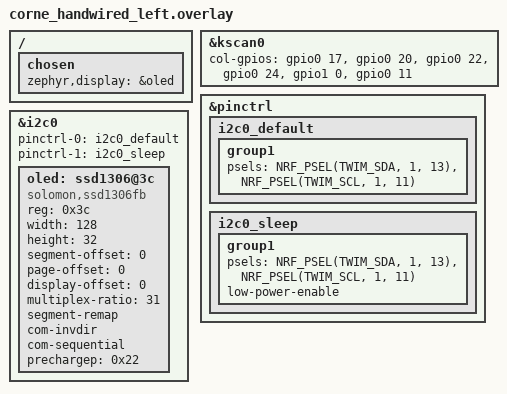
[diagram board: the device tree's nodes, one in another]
/*
 * Left Half - Corne Handwired
 * Display (SSD1306, 128x32, I2C @ 0x3C): SDA=P1.13, SCL=P1.11
 * Encoder removed for now; will be moved to the right half later.
 */

#include "corne_handwired.dtsi"

&kscan0 {
    col-gpios
        = <&gpio0 17 GPIO_ACTIVE_HIGH>
        , <&gpio0 20 GPIO_ACTIVE_HIGH>
        , <&gpio0 22 GPIO_ACTIVE_HIGH>
        , <&gpio0 24 GPIO_ACTIVE_HIGH>
        , <&gpio1 0  GPIO_ACTIVE_HIGH>
        , <&gpio0 11 GPIO_ACTIVE_HIGH>
        ;
};

&pinctrl {
    i2c0_default: i2c0_default {
        group1 {
            psels = <NRF_PSEL(TWIM_SDA, 1, 13)>,
                    <NRF_PSEL(TWIM_SCL, 1, 11)>;
        };
    };

    i2c0_sleep: i2c0_sleep {
        group1 {
            psels = <NRF_PSEL(TWIM_SDA, 1, 13)>,
                    <NRF_PSEL(TWIM_SCL, 1, 11)>;
            low-power-enable;
        };
    };
};

&i2c0 {
    status = "okay";
    pinctrl-0 = <&i2c0_default>;
    pinctrl-1 = <&i2c0_sleep>;
    pinctrl-names = "default", "sleep";

    oled: ssd1306@3c {
        compatible = "solomon,ssd1306fb";
        reg = <0x3c>;
        width = <128>;
        height = <32>;
        segment-offset = <0>;
        page-offset = <0>;
        display-offset = <0>;
        multiplex-ratio = <31>;
        segment-remap;
        com-invdir;
        com-sequential;
        prechargep = <0x22>;
    };
};

/ {
    chosen {
        zephyr,display = &oled;
    };
};
